# CY8C5868AXI_LP035 register map
File version: 0.1
CY8C58LP
Registers are 8-bit, read-write, no defined reset value unless marked. A register's access mark holds for its fields unless they carry their own. Offsets are from the block's base; lines under a group give offsets from that group; [hi:lo] are bit positions; {n}, {i} and the like mark numbered series; 'fields as' and 'values as' point back to an identical list; <NAME> marks a mode.

## Memory map
0x00000000 UART_3 — UART
0x00000000 UART_1 — UART
0x00000000 UART_2 — UART

## UART_3 — UART
Base 0x00000000
0x40006440 TX_UART_3_TX_DATA — TX Data Register
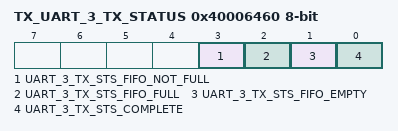
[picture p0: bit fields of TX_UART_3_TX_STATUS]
0x40006460 TX_UART_3_TX_STATUS — TX status register
  [3] UART_3_TX_STS_FIFO_NOT_FULL ro, [2] UART_3_TX_STS_FIFO_FULL ro, [1] UART_3_TX_STS_FIFO_EMPTY ro, [0] UART_3_TX_STS_COMPLETE ro

## UART_1 — UART
Base 0x00000000
0x40006444 TX_UART_1_TX_DATA — TX Data Register
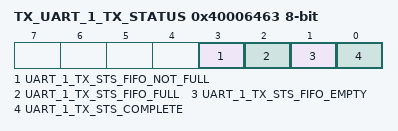
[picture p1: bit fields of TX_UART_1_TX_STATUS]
0x40006463 TX_UART_1_TX_STATUS — TX status register
  [3] UART_1_TX_STS_FIFO_NOT_FULL ro, [2] UART_1_TX_STS_FIFO_FULL ro, [1] UART_1_TX_STS_FIFO_EMPTY ro, [0] UART_1_TX_STS_COMPLETE ro

## UART_2 — UART
Base 0x00000000
0x40006441 TX_UART_2_TX_DATA — TX Data Register
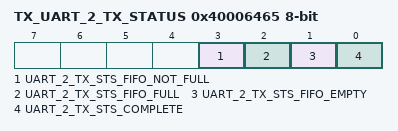
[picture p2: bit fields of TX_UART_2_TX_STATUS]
0x40006465 TX_UART_2_TX_STATUS — TX status register
  [3] UART_2_TX_STS_FIFO_NOT_FULL ro, [2] UART_2_TX_STS_FIFO_FULL ro, [1] UART_2_TX_STS_FIFO_EMPTY ro, [0] UART_2_TX_STS_COMPLETE ro
